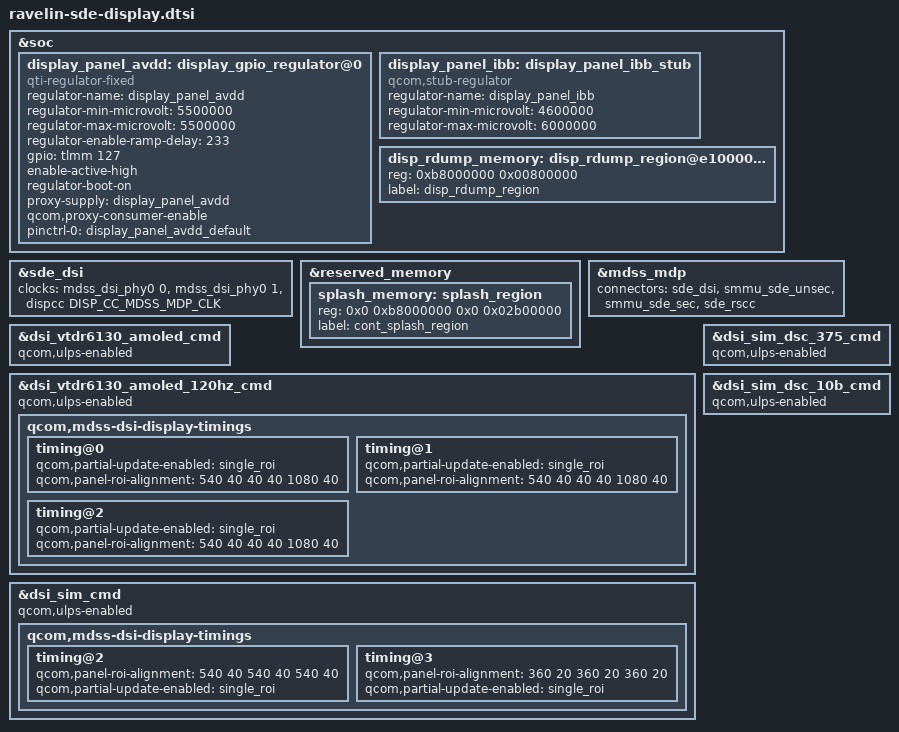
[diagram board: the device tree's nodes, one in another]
#include <dt-bindings/clock/qcom,dispcc-ravelin.h>
#include "ravelin-sde-display-common.dtsi"

&soc {
	display_panel_avdd: display_gpio_regulator@0 {
		compatible = "qti-regulator-fixed";
		regulator-name = "display_panel_avdd";
		regulator-min-microvolt = <5500000>;
		regulator-max-microvolt = <5500000>;
		regulator-enable-ramp-delay = <233>;
		gpio = <&tlmm 127 0>;
		enable-active-high;
		regulator-boot-on;
		proxy-supply = <&display_panel_avdd>;
		qcom,proxy-consumer-enable;
		pinctrl-names = "default";
		pinctrl-0 = <&display_panel_avdd_default>;
	};

	display_panel_ibb: display_panel_ibb_stub {
		compatible = "qcom,stub-regulator";
		regulator-name = "display_panel_ibb";
		regulator-min-microvolt = <4600000>;
		regulator-max-microvolt = <6000000>;
	};

	disp_rdump_memory: disp_rdump_region@e1000000 {
		reg = <0xb8000000 0x00800000>;
		label = "disp_rdump_region";
	};
};

&sde_dsi {
	clocks = <&mdss_dsi_phy0 0>,
			<&mdss_dsi_phy0 1>,
			 /*
			  * Currently the dsi clock handles are under the dsi
			  * controller DT node. As soon as the controller probe
			  * finishes, the dispcc sync state can get called before
			  * the dsi_display probe potentially disturbing the clock
			  * votes for cont_splash use case. Hence we are no longer
			  * protected by the component model in this case against the
			  * disp cc sync state getting triggered after the dsi_ctrl
			  * probe. To protect against this incorrect sync state trigger
			  * add this dummy MDP clk vote handle to the dsi_display
			  * DT node. Since the dsi_display driver does not parse
			  * MDP clock nodes, no actual vote shall be added and this
			  * change is done just to satisfy sync state requirements.
			  */
			 <&dispcc DISP_CC_MDSS_MDP_CLK>;
	clock-names = "pll_byte_clk0", "pll_dsi_clk0",
			"mdp_core_clk";
};

&reserved_memory {
	splash_memory: splash_region {
		reg = <0x0 0xb8000000 0x0 0x02b00000>;
		label = "cont_splash_region";
	};
};

&mdss_mdp {
	connectors = <&sde_dsi &smmu_sde_unsec &smmu_sde_sec &sde_rscc>;
};

&dsi_vtdr6130_amoled_cmd {
	qcom,ulps-enabled;
};

&dsi_vtdr6130_amoled_120hz_cmd {
	qcom,ulps-enabled;
	qcom,mdss-dsi-display-timings {
		timing@0 {
			qcom,partial-update-enabled = "single_roi";
			qcom,panel-roi-alignment = <540 40 40 40 1080 40>;
		};
		timing@1 {
			qcom,partial-update-enabled = "single_roi";
			qcom,panel-roi-alignment = <540 40 40 40 1080 40>;
		};
		timing@2 {
			qcom,partial-update-enabled = "single_roi";
			qcom,panel-roi-alignment = <540 40 40 40 1080 40>;
		};
	};
};

&dsi_sim_cmd{
	qcom,ulps-enabled;
	qcom,mdss-dsi-display-timings {
		timing@2 { /* FHD 60FPS cmd mode*/
			qcom,panel-roi-alignment = <540 40 540 40 540 40>;
			qcom,partial-update-enabled = "single_roi";
		};
		timing@3 { /* HD 60FPS cmd mode*/
			qcom,panel-roi-alignment = <360 20 360 20 360 20>;
			qcom,partial-update-enabled = "single_roi";
		};
	};
};

&dsi_sim_dsc_375_cmd {
	qcom,ulps-enabled;
};

&dsi_sim_dsc_10b_cmd {
	qcom,ulps-enabled;
};
